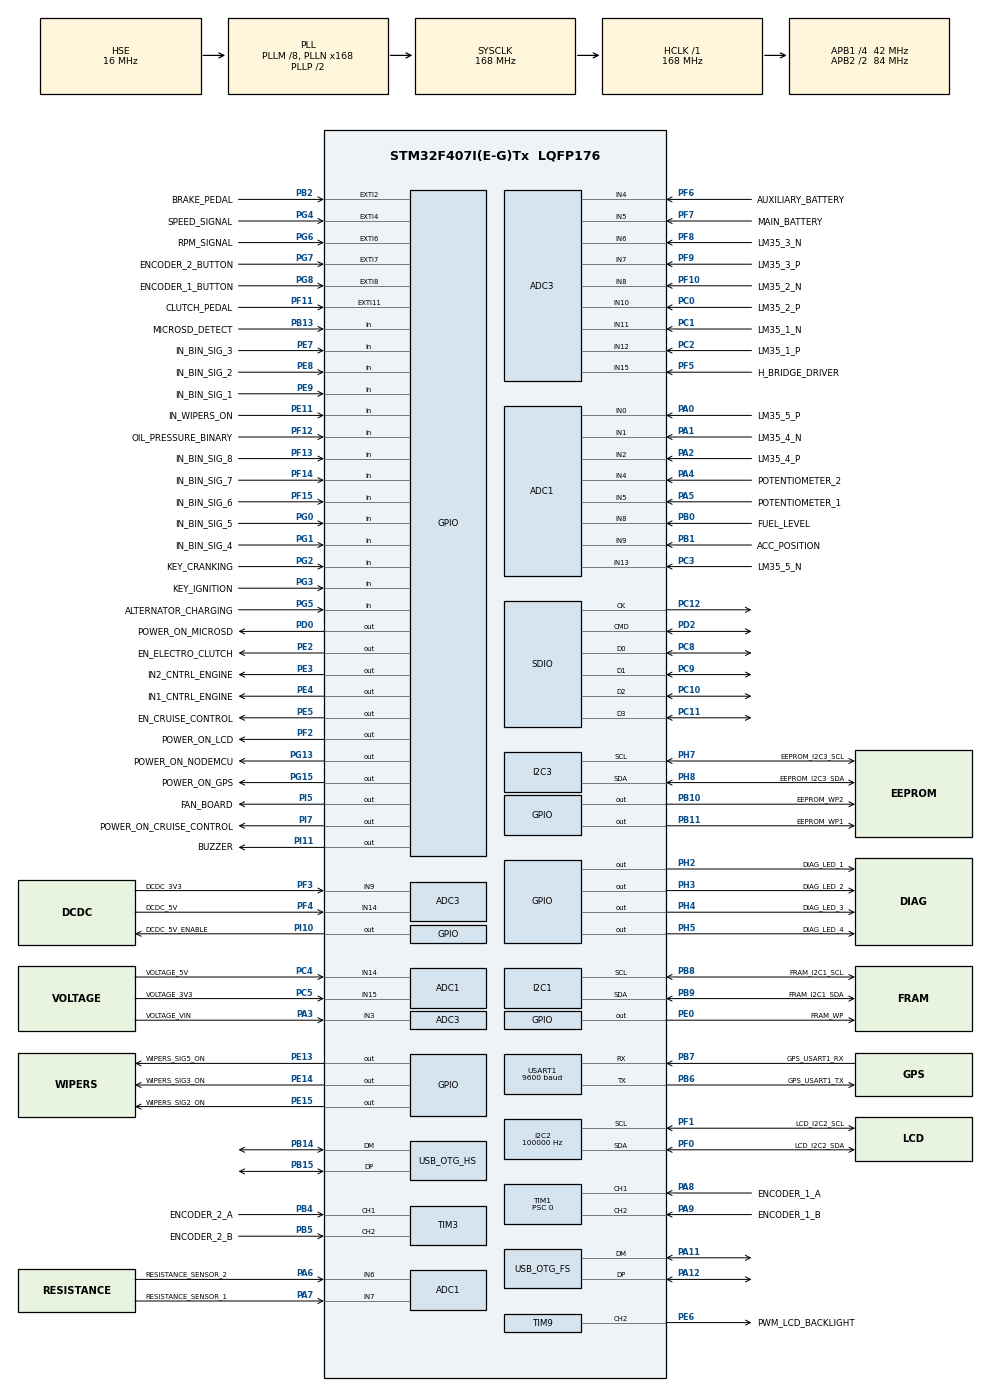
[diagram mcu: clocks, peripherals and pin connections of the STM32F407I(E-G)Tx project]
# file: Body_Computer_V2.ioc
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Dma.SDIO_RX.4.MemBurst=DMA_MBURST_INC4
FREERTOS.Queues01=Queue_EEPROM_read,5,EEPROM_data_struct,0,Dynamic,NULL,NULL;Queue_EEPROM_write,5,EEPROM_data_struct,0,Dynamic,NULL,NULL;Queue_error_snapshot_dump,5,Error_Code,0,Dynamic,NULL,NULL;Queue_diagnostic_snapshot_dump,5,Diagnostic_Snapshot_struct,0,Dynamic,NULL,NULL
PF4.Mode=IN14
FATFS._USE_LFN=3
NVIC.I2C1_EV_IRQn=true\:5\:0\:false\:false\:true\:true\:true\:true
FATFS0.BSP.api=Unknown
VP_ADC1_TempSens_Input.Mode=IN-TempSens
NVIC.TIM6_DAC_IRQn=true\:0\:0\:false\:false\:true\:false\:false\:true
PG8.Signal=GPXTI8
PG0.Signal=GPIO_Input
I2C2.NoStretchMode=I2C_NOSTRETCH_DISABLE
ADC1.SamplingTime-12\#ChannelRegularConversion=ADC_SAMPLETIME_480CYCLES
FREERTOS.configENABLE_FPU=1
PG15.GPIO_Label=POWER_ON_GPS
ADC1.Channel-5\#ChannelRegularConversion=ADC_CHANNEL_6
PF7.Signal=ADC3_IN5
ADC3.Rank-7\#ChannelRegularConversion=8
ADC1.Rank-11\#ChannelRegularConversion=12
RCC.APB2TimFreq_Value=168000000
PB6.Signal=USART1_TX
Dma.ADC1.0.Direction=DMA_PERIPH_TO_MEMORY
PD0.Signal=GPIO_Output
ADC3.ScanConvMode=ENABLE
Dma.ADC1.0.MemDataAlignment=DMA_MDATAALIGN_HALFWORD
FATFS0.BSP.ip=GPIO
NVIC.EXTI15_10_IRQn=true\:5\:0\:false\:false\:true\:true\:true\:true
Dma.I2C2_TX.2.Priority=DMA_PRIORITY_LOW
PB3.Mode=Trace_Asynchronous_SW
ADC1.ScanConvMode=ENABLE
PF1.GPIO_Label=LCD_I2C2_SCL
SH.ADCx_IN15.0=ADC1_IN15,IN15
PF12.GPIO_Label=OIL_PRESSURE_BINARY
I2C1.NoStretchMode=I2C_NOSTRETCH_ENABLE
PC4.GPIO_Label=VOLTAGE_5V
PE9.Signal=GPIO_Input
PB14.Mode=Device_Only_FS
ADC3.SamplingTime-5\#ChannelRegularConversion=ADC_SAMPLETIME_480CYCLES
PB1.GPIO_Label=ACC_POSITION
PE4.GPIO_Label=IN1_CNTRL_ENGINE
PG4.GPIO_Label=SPEED_SIGNAL
SH.ADCx_IN8.0=ADC1_IN8,IN8
PC9.Mode=SD_4_bits_Wide_bus
PA8.Signal=S_TIM1_CH1
VP_FREERTOS_VS_CMSIS_V1.Mode=CMSIS_V1
Dma.I2C2_RX.3.PeriphDataAlignment=DMA_PDATAALIGN_BYTE
Dma.SDIO_TX.5.PeriphDataAlignment=DMA_PDATAALIGN_WORD
TIM9.Prescaler=2
USB_DEVICE.USBD_SELF_POWERED-MSC_HS=0
Mcu.Package=LQFP176
PB9.Signal=I2C1_SDA
PB1.Signal=ADCx_IN9
NVIC.TimeBase=TIM6_DAC_IRQn
USB_DEVICE.VirtualMode-MSC_HS=Msc
ADC3.Rank-0\#ChannelRegularConversion=1
NVIC.TimeBaseIP=TIM6
PC11.Mode=SD_4_bits_Wide_bus
ADC3.DMAContinuousRequests=ENABLE
RCC.APB2CLKDivider=RCC_HCLK_DIV2
Dma.SDIO_RX.4.PeriphDataAlignment=DMA_PDATAALIGN_WORD
NVIC.EXTI2_IRQn=true\:5\:0\:false\:false\:true\:true\:true\:true
RCC.APB1TimFreq_Value=84000000
FREERTOS.configGENERATE_RUN_TIME_STATS=1
PF10.Mode=IN8
PH8.Mode=I2C
PA4.GPIO_Label=POTENTIOMETER_2
ADC1.EOCSelection=ADC_EOC_SEQ_CONV
Dma.ADC3.1.Priority=DMA_PRIORITY_LOW
ADC1.Rank-4\#ChannelRegularConversion=5
TIM9.Channel-PWM\ Generation2\ CH2=TIM_CHANNEL_2
FATFS0.BSP.STBoard=false
FREERTOS.Tasks01=My_StartUp_Task,2,128,StartStartUpTask,Default,NULL,Dynamic,NULL,NULL;My_CruiseCntrl,1,256,StartCruiseCntrlTask,As external,NULL,Dynamic,NULL,NULL;My_500ms_Task,0,128,Start500msTask,As external,NULL,Dynamic,NULL,NULL;My_LCD_Task,0,512,StartLCDTask,As external,NULL,Dynamic,NULL,NULL;My_GPS_Task,0,448,StartGPSTask,As external,NULL,Dynamic,NULL,NULL;My_EEPROM_Task,1,128,StartEEPROMTask,As external,NULL,Dynamic,NULL,NULL;My_DumpToEEPROM,-1,128,StartDumpToEEPROMTask,As external,NULL,Dynamic,NULL,NULL;My_DumpToSDCard,-1,1536,StartDumpToSDCardTask,As external,NULL,Dynamic,NULL,NULL;My_Measure_Task,0,384,StartMeasureTask,As external,NULL,Dynamic,NULL,NULL;My_50ms_Task,0,128,Start50msTask,As external,NULL,Dynamic,NULL,NULL;My_DiagCheck_Ta,1,256,StartDiagCheckTask,As external,NULL,Dynamic,NULL,NULL;My_AlarmControl,0,256,StartAlarmControlTask,As external,NULL,Dynamic,NULL,NULL
SH.ADCx_IN6.0=ADC1_IN6,IN6
PG5.Signal=GPIO_Input
ADC3.Rank-6\#ChannelRegularConversion=7
FATFS0.BSP.mode=Input
FREERTOS.INCLUDE_vTaskDelayUntil=1
PC2.Signal=ADCx_IN12
Dma.SDIO_TX.5.Direction=DMA_MEMORY_TO_PERIPH
USB_OTG_HS.VirtualMode-Device_Only_FS=Device_Only_FS
PF8.GPIO_Label=LM35_3_N
PG8.GPIO_PuPd=GPIO_NOPULL
TIM9.Pulse-PWM\ Generation2\ CH2=1
PB8.GPIO_Label=FRAM_I2C1_SCL
PA8.GPIO_Label=ENCODER_1_A
TIM3.IC2Filter=15
ADC3.SamplingTime-6\#ChannelRegularConversion=ADC_SAMPLETIME_480CYCLES
PE8.GPIO_Label=IN_BIN_SIG_2
Dma.ADC1.0.Priority=DMA_PRIORITY_LOW
SDIO.ClockDiv=3
NVIC.DMA2_Stream6_IRQn=true\:5\:0\:false\:false\:true\:true\:false\:true
PB14.Signal=USB_OTG_HS_DM
PA5.Signal=ADCx_IN5
TIM3.IC1Filter=15
PC12.Mode=SD_4_bits_Wide_bus
ADC1.Rank-12\#ChannelRegularConversion=13
PI7.Signal=GPIO_Output
PE14.Signal=GPIO_Output
ADC3.Channel-5\#ChannelRegularConversion=ADC_CHANNEL_4
PB4.GPIO_Label=ENCODER_2_A
PG7.GPIO_Label=ENCODER_2_BUTTON
PF4.GPIO_Label=DCDC_5V
PA1.GPIO_Label=LM35_4_N
SH.ADCx_IN4.0=ADC1_IN4,IN4
FREERTOS.configUSE_MUTEXES=0
PF13.Signal=GPIO_Input
ADC1.Rank-9\#ChannelRegularConversion=10
FREERTOS.INCLUDE_uxTaskGetStackHighWaterMark2=1
PC8.Mode=SD_4_bits_Wide_bus
ADC3.Rank-1\#ChannelRegularConversion=2
Dma.SDIO_RX.4.PeriphInc=DMA_PINC_DISABLE
ADC1.master=1
PA5.GPIO_Label=POTENTIOMETER_1
Dma.SDIO_RX.4.FIFOThreshold=DMA_FIFO_THRESHOLD_FULL
PE5.GPIO_Label=EN_CRUISE_CONTROL
ProjectManager.HeapSize=0x2000
ADC3.EOCSelection=ADC_EOC_SEQ_CONV
NVIC.PriorityGroup=NVIC_PRIORITYGROUP_4
PF0.GPIO_Label=LCD_I2C2_SDA
PI11.GPIO_Label=BUZZER
PE3.Signal=GPIO_Output
PF4.Signal=ADC3_IN14
ADC1.SamplingTime-9\#ChannelRegularConversion=ADC_SAMPLETIME_480CYCLES
PD2.Signal=SDIO_CMD
ADC1.Rank-5\#ChannelRegularConversion=6
FATFS0.BSP.name=Detect_SDIO
Mcu.Family=STM32F4
Dma.SDIO_TX.5.MemInc=DMA_MINC_ENABLE
NVIC.OTG_HS_IRQn=true\:5\:0\:false\:false\:true\:true\:false\:true
USB_DEVICE.CLASS_NAME_FS=DFU
ADC1.ContinuousConvMode=ENABLE
ADC3.Channel-3\#ChannelRegularConversion=ADC_CHANNEL_15
PG2.Signal=GPIO_Input
ADC3.Channel-11\#ChannelRegularConversion=ADC_CHANNEL_7
PE11.GPIO_Label=IN_WIPERS_ON
USART1.BaudRate=9600
PD0.GPIO_Label=POWER_ON_MICROSD
TIM1.EncoderMode=TIM_ENCODERMODE_TI12
PA11.Mode=Device_Only
PB13.GPIO_Label=MICROSD_DETECT
PG5.GPIO_Label=ALTERNATOR_CHARGING
PB15.Signal=USB_OTG_HS_DP
VP_USB_DEVICE_VS_USB_DEVICE_DFU_FS.Mode=DFU_FS
ADC3.Channel-0\#ChannelRegularConversion=ADC_CHANNEL_3
PG15.Signal=GPIO_Output
ADC3.Rank-2\#ChannelRegularConversion=3
Dma.SDIO_TX.5.FIFOThreshold=DMA_FIFO_THRESHOLD_FULL
ADC3.Channel-6\#ChannelRegularConversion=ADC_CHANNEL_11
Dma.ADC3.1.PeriphDataAlignment=DMA_PDATAALIGN_HALFWORD
TIM1.Prescaler=0
PE11.GPIO_PuPd=GPIO_PULLDOWN
ADC1.Channel-3\#ChannelRegularConversion=ADC_CHANNEL_4
SH.ADCx_IN3.0=ADC3_IN3,IN3
Dma.SDIO_RX.4.FIFOMode=DMA_FIFOMODE_ENABLE
PG5.GPIO_PuPd=GPIO_PULLDOWN
TIM7.Period=4199
Dma.SDIO_RX.4.MemDataAlignment=DMA_MDATAALIGN_WORD
ADC1.Channel-0\#ChannelRegularConversion=ADC_CHANNEL_14
RCC.HSE_VALUE=16000000
FREERTOS.configUSE_TIMERS=1
PE13.GPIO_PuPd=GPIO_PULLDOWN
FREERTOS.configENABLE_BACKWARD_COMPATIBILITY=0
PF9.Mode=IN7
Dma.I2C2_TX.2.MemInc=DMA_MINC_ENABLE
PA14.Mode=Trace_Asynchronous_SW
PH7.GPIO_Label=EEPROM_I2C3_SCL
PF11.Signal=GPXTI11
PG6.GPIO_ModeDefaultEXTI=GPIO_MODE_IT_RISING
PB7.Signal=USART1_RX
Dma.SDIO_RX.4.Mode=DMA_PFCTRL
SH.S_TIM3_CH1.0=TIM3_CH1,Encoder_Interface
NVIC.DMA1_Stream7_IRQn=true\:5\:0\:false\:false\:true\:true\:false\:true
PH1-OSC_OUT.Mode=HSE-External-Oscillator
PB7.GPIO_Label=GPS_USART1_RX
PA6.Signal=ADCx_IN6
NVIC.OTG_FS_IRQn=true\:5\:0\:false\:false\:true\:true\:false\:true
IWDG.Reload=600
USB_DEVICE.CLASS_NAME_HS=MSC
PF8.Signal=ADC3_IN6
PG0.GPIO_Label=IN_BIN_SIG_5
Dma.SDIO_RX.4.Direction=DMA_PERIPH_TO_MEMORY
PG4.GPIO_ModeDefaultEXTI=GPIO_MODE_IT_RISING_FALLING
SH.ADCx_IN1.0=ADC1_IN1,IN1
PB5.GPIO_Label=ENCODER_2_B
Dma.Request2=I2C2_TX
Dma.Request1=ADC3
Dma.Request4=SDIO_RX
Dma.Request3=I2C2_RX
Dma.SDIO_RX.4.Priority=DMA_PRIORITY_LOW
Dma.Request5=SDIO_TX
PC5.Signal=ADCx_IN15
PE7.Signal=GPIO_Input
ADC1.Rank-6\#ChannelRegularConversion=7
Dma.Request0=ADC1
PF3.GPIO_Label=DCDC_3V3
ADC1.SamplingTime-8\#ChannelRegularConversion=ADC_SAMPLETIME_480CYCLES
PE2.GPIO_Label=EN_ELECTRO_CLUTCH
PB4.Signal=S_TIM3_CH1
PG2.GPIO_Label=KEY_CRANKING
PA3.Signal=ADCx_IN3
Dma.SDIO_TX.5.Mode=DMA_PFCTRL
ADC3.SamplingTime-3\#ChannelRegularConversion=ADC_SAMPLETIME_480CYCLES
SH.ADCx_IN13.0=ADC1_IN13,IN13
PG7.Signal=GPXTI7
ADC1.Rank-10\#ChannelRegularConversion=11
ADC1.Rank-8\#ChannelRegularConversion=9
PC11.Signal=SDIO_D3
PC8.Signal=SDIO_D0
PC10.Mode=SD_4_bits_Wide_bus
Dma.I2C2_TX.2.Mode=DMA_NORMAL
Dma.I2C2_RX.3.PeriphInc=DMA_PINC_DISABLE
PE14.GPIO_Label=WIPERS_SIG3_ON
ADC3.SamplingTime-10\#ChannelRegularConversion=ADC_SAMPLETIME_480CYCLES
PF5.Mode=IN15
NVIC.SDIO_IRQn=true\:5\:0\:false\:false\:true\:true\:true\:true
Dma.SDIO_RX.4.Instance=DMA2_Stream3
FATFS0.BSP.instance=PB13
PG8.GPIO_Label=ENCODER_1_BUTTON
PA13.Signal=SYS_JTMS-SWDIO
Dma.ADC1.0.PeriphDataAlignment=DMA_PDATAALIGN_HALFWORD
ADC3.SamplingTime-0\#ChannelRegularConversion=ADC_SAMPLETIME_480CYCLES
SH.S_TIM1_CH1.0=TIM1_CH1,Encoder_Interface
PF6.Signal=ADC3_IN4
FREERTOS.configRECORD_STACK_HIGH_ADDRESS=1
PB10.GPIO_Label=EEPROM_WP2
FREERTOS.configUSE_TRACE_FACILITY=1
PH8.Signal=I2C3_SDA
PB9.Mode=I2C
PF9.GPIO_Label=LM35_3_P
PA1.Signal=ADCx_IN1
PD2.Mode=SD_4_bits_Wide_bus
board=custom
Dma.I2C2_TX.2.PeriphInc=DMA_PINC_DISABLE
RCC.VCOOutputFreq_Value=336000000
PH4.GPIO_Label=DIAG_LED_3
PB15.Mode=Device_Only_FS
ADC1.Channel-12\#ChannelRegularConversion=ADC_CHANNEL_TEMPSENSOR
SH.ADCx_IN11.0=ADC3_IN11,IN11
PC1.GPIO_Label=LM35_1_N
PF15.GPIO_Label=IN_BIN_SIG_6
Dma.ADC3.1.MemInc=DMA_MINC_ENABLE
ADC3.SamplingTime-8\#ChannelRegularConversion=ADC_SAMPLETIME_480CYCLES
PE14.GPIO_PuPd=GPIO_PULLDOWN
PF1.Signal=I2C2_SCL
ADC1.NbrOfConversion=13
Dma.ADC3.1.Mode=DMA_CIRCULAR
PE0.Signal=GPIO_Output
PE7.GPIO_Label=IN_BIN_SIG_3
FATFS._MAX_SS=512
RCC.48MHZClocksFreq_Value=48000000
RCC.SYSCLKFreq_VALUE=168000000
ADC1.SamplingTime-3\#ChannelRegularConversion=ADC_SAMPLETIME_480CYCLES
ADC1.Rank-3\#ChannelRegularConversion=4
NVIC.EXTI9_5_IRQn=true\:5\:0\:false\:false\:true\:true\:true\:true
Dma.ADC1.0.MemInc=DMA_MINC_ENABLE
Dma.SDIO_TX.5.FIFOMode=DMA_FIFOMODE_ENABLE
PB2.GPIO_Label=BRAKE_PEDAL
PG4.GPIO_PuPd=GPIO_PULLDOWN
NVIC.I2C2_EV_IRQn=true\:5\:0\:false\:false\:true\:true\:true\:true
RCC.HSI_VALUE=16000000
RCC.PLLQ=7
PH3.Signal=GPIO_Output
RCC.PLLM=8
RCC.PLLN=168
ADC3.Rank-11\#ChannelRegularConversion=12
PE5.GPIO_Speed=GPIO_SPEED_FREQ_HIGH
ADC3.NbrOfConversionFlag=1
Dma.SDIO_RX.4.PeriphBurst=DMA_PBURST_INC4
Dma.SDIO_TX.5.Instance=DMA2_Stream6
PA3.GPIO_Label=VOLTAGE_VIN
PH0-OSC_IN.Signal=RCC_OSC_IN
VP_SYS_VS_tim6.Mode=TIM6
VP_FATFS_VS_SDIO.Mode=SDIO
PG4.Signal=GPXTI4
ADC1.SamplingTime-6\#ChannelRegularConversion=ADC_SAMPLETIME_480CYCLES
NVIC.DMA1_Stream2_IRQn=true\:5\:0\:false\:false\:true\:true\:false\:true
PC12.Signal=SDIO_CK
PG6.GPIO_Label=RPM_SIGNAL
PA6.GPIO_Label=RESISTANCE_SENSOR_2
PB6.GPIO_Label=GPS_USART1_TX
PB13.Signal=GPIO_Input
PG13.Signal=GPIO_Output
PE6.GPIO_Label=PWM_LCD_BACKLIGHT
PF6.GPIO_Label=AUXILIARY_BATTERY 
ADC1.Channel-8\#ChannelRegularConversion=ADC_CHANNEL_1
RCC.SYSCLKSource=RCC_SYSCLKSOURCE_PLLCLK
ADC3.Channel-8\#ChannelRegularConversion=ADC_CHANNEL_8
PH5.Signal=GPIO_Output
ADC1.Channel-2\#ChannelRegularConversion=ADC_CHANNEL_5
PB6.Mode=Asynchronous
PC3.Signal=ADCx_IN13
PE5.Signal=GPIO_Output
Dma.I2C2_TX.2.Direction=DMA_MEMORY_TO_PERIPH
PF10.GPIO_Label=LM35_2_N
PB2.Signal=GPXTI2
FATFS0.BSP.i2caddr=0
ADC3.SamplingTime-2\#ChannelRegularConversion=ADC_SAMPLETIME_480CYCLES
PG6.GPIO_PuPd=GPIO_PULLDOWN
Dma.I2C2_RX.3.Priority=DMA_PRIORITY_LOW
Dma.ADC1.0.PeriphInc=DMA_PINC_DISABLE
ADC3.ContinuousConvMode=ENABLE
PE2.Signal=GPIO_Output
PF8.Mode=IN6
ADC3.SamplingTime-9\#ChannelRegularConversion=ADC_SAMPLETIME_480CYCLES
PF3.Signal=ADC3_IN9
ADC3.Channel-2\#ChannelRegularConversion=ADC_CHANNEL_14
ADC3.Rank-4\#ChannelRegularConversion=5
ADC1.SamplingTime-0\#ChannelRegularConversion=ADC_SAMPLETIME_480CYCLES
SH.ADCx_IN14.0=ADC1_IN14,IN14
Dma.I2C2_TX.2.FIFOMode=DMA_FIFOMODE_DISABLE
FATFS0.BSP.solution=PB13
SH.ADCx_IN9.0=ADC1_IN9,IN9
PH2.Signal=GPIO_Output
Dma.SDIO_TX.5.PeriphInc=DMA_PINC_DISABLE
Dma.I2C2_RX.3.MemInc=DMA_MINC_ENABLE
PF14.Signal=GPIO_Input
Dma.ADC1.0.FIFOMode=DMA_FIFOMODE_DISABLE
Dma.I2C2_TX.2.Instance=DMA1_Stream7
PI11.Signal=GPIO_Output
NVIC.USART1_IRQn=true\:5\:0\:false\:false\:true\:true\:true\:true
TIM9.Period=9999
PI10.GPIO_Label=DCDC_5V_ENABLE
ADC1.Channel-10\#ChannelRegularConversion=ADC_CHANNEL_13
FREERTOS.configTIMER_QUEUE_LENGTH=50
NVIC.EXTI4_IRQn=true\:5\:0\:false\:false\:true\:true\:true\:true
Dma.I2C2_TX.2.MemDataAlignment=DMA_MDATAALIGN_BYTE
Dma.SDIO_TX.5.MemDataAlignment=DMA_MDATAALIGN_WORD
Dma.ADC1.0.Instance=DMA2_Stream0
ADC1.Rank-0\#ChannelRegularConversion=1
ADC3.Rank-10\#ChannelRegularConversion=11
PA9.GPIO_Label=ENCODER_1_B
FREERTOS.configCHECK_FOR_STACK_OVERFLOW=1
PB11.GPIO_Label=EEPROM_WP1
PF14.GPIO_Label=IN_BIN_SIG_7
NVIC.DMA2_Stream1_IRQn=true\:5\:0\:false\:false\:true\:true\:false\:true
PC0.Signal=ADCx_IN10
RCC.APB1CLKDivider=RCC_HCLK_DIV4
PF13.GPIO_Label=IN_BIN_SIG_8
PG13.GPIO_Label=POWER_ON_NODEMCU
VP_USB_DEVICE_VS_USB_DEVICE_MSC_HS.Mode=MSC_HS
PA0-WKUP.GPIO_Label=LM35_5_P
PA0-WKUP.Signal=ADCx_IN0
ADC1.Channel-7\#ChannelRegularConversion=ADC_CHANNEL_9
PF1.Mode=I2C
SH.S_TIM9_CH2.0=TIM9_CH2,PWM Generation2 CH2
SH.ADCx_IN7.0=ADC1_IN7,IN7
PA9.Signal=S_TIM1_CH2
ADC3.NbrOfConversion=12
Dma.ADC3.1.FIFOMode=DMA_FIFOMODE_DISABLE
PE9.GPIO_Label=IN_BIN_SIG_1
Dma.SDIO_TX.5.Priority=DMA_PRIORITY_LOW
Dma.ADC3.1.Instance=DMA2_Stream1
PB10.Signal=GPIO_Output
ADC3.Rank-9\#ChannelRegularConversion=10
FATFS.BSP.number=1
PE15.Signal=GPIO_Output
PE8.Signal=GPIO_Input
Dma.ADC3.1.MemDataAlignment=DMA_MDATAALIGN_HALFWORD
TIM1.IC2Filter=15
Dma.ADC3.1.PeriphInc=DMA_PINC_DISABLE
ADC1.SamplingTime-10\#ChannelRegularConversion=ADC_SAMPLETIME_480CYCLES
ADC1.DMAContinuousRequests=ENABLE
ADC3.Rank-5\#ChannelRegularConversion=6
PA13.Mode=Trace_Asynchronous_SW
ADC3.Channel-1\#ChannelRegularConversion=ADC_CHANNEL_9
PA4.Signal=ADCx_IN4
ADC1.SamplingTime-1\#ChannelRegularConversion=ADC_SAMPLETIME_480CYCLES
PB5.Signal=S_TIM3_CH2
PE13.GPIO_Label=WIPERS_SIG5_ON
TIM1.IC1Filter=15
USART1.VirtualMode=VM_ASYNC
ADC1.Rank-1\#ChannelRegularConversion=2
PA11.Signal=USB_OTG_FS_DM
Dma.SDIO_TX.5.MemBurst=DMA_MBURST_INC4
ADC1.SamplingTime-5\#ChannelRegularConversion=ADC_SAMPLETIME_480CYCLES
PF6.Mode=IN4
PF9.Signal=ADC3_IN7
FREERTOS.Timers01=My_Timer_ENC_Menu_Button,ENC_Menu_Button_LongPress_Callback,osTimerOnce,Default,NULL,Dynamic,NULL;My_Timer_ENC_Cruise_Button,ENC_Cruise_Button_LongPress_Callback,osTimerOnce,Default,NULL,Dynamic,NULL;My_Timer_carWaterTempValueCheck,Timer_carWaterTempValueCheck,osTimerOnce,As external,NULL,Dynamic,NULL;My_Timer_carOilTempValueCheck,Timer_carOilTempValueCheck,osTimerOnce,As external,NULL,Dynamic,NULL;My_Timer_carOilAnalogPressureValueCheck,Timer_carOilAnalogPressureValueCheck,osTimerOnce,As external,NULL,Dynamic,NULL;My_Timer_carMainBattVoltageValueCheck,Timer_carMainBattVoltageValueCheck,osTimerOnce,As external,NULL,Dynamic,NULL;My_Timer_carFuelLevelValueCheck,Timer_carFuelLevelValueCheck,osTimerOnce,As external,NULL,Dynamic,NULL;My_Timer_board3V3VoltageValueCheck,Timer_board3V3VoltageValueCheck,osTimerOnce,As external,NULL,Dynamic,NULL;My_Timer_board5VVoltageValueCheck,Timer_board5VVoltageValueCheck,osTimerOnce,As external,NULL,Dynamic,NULL;My_Timer_boardVinVoltageValueCheck,Timer_boardVinVoltageValueCheck,osTimerOnce,As external,NULL,Dynamic,NULL;My_Timer_board3V3TempValueCheck,Timer_board3V3TempValueCheck,osTimerOnce,As external,NULL,Dynamic,NULL;My_Timer_board5VTempValueCheck,Timer_board5VTempValueCheck,osTimerOnce,As external,NULL,Dynamic,NULL;My_Timer_boardHBridgeTempValueCheck,Timer_boardHBridgeTempValueCheck,osTimerOnce,As external,NULL,Dynamic,NULL;My_Timer_carOilBinaryPressureValueCheck,Timer_carOilBinaryPressureValueCheck,osTimerOnce,As external,NULL,Dynamic,NULL;My_Timer_Buzzer,Timer_Buzzer,osTimerOnce,As external,NULL,Dynamic,NULL;My_Timer_carAuxBattVoltageValueCheck,Timer_carAuxBattVoltageValueCheck,osTimerOnce,As external,NULL,Dynamic,NULL;My_Timer_LCD_Backlight,Timer_LCD_Backlight,osTimerOnce,As external,NULL,Dynamic,NULL;My_Timer_WIPERS,Timer_WIPERS,osTimerOnce,As external,NULL,Dynamic,NULL
SH.ADCx_IN5.0=ADC1_IN5,IN5
PB8.Mode=I2C
PF12.GPIO_PuPd=GPIO_PULLDOWN
PC3.GPIO_Label=LM35_5_N
PG3.GPIO_Label=KEY_IGNITION
PB0.Signal=ADCx_IN8
PC1.Signal=ADCx_IN11
PH2.GPIO_Label=DIAG_LED_1
RCC.CortexFreq_Value=168000000
PG6.Signal=GPXTI6
ADC3.SamplingTime-7\#ChannelRegularConversion=ADC_SAMPLETIME_480CYCLES
SH.ADCx_IN2.0=ADC1_IN2,IN2
PC10.Signal=SDIO_D2
VP_IWDG_VS_IWDG.Mode=IWDG_Activate
ADC3.SamplingTime-11\#ChannelRegularConversion=ADC_SAMPLETIME_480CYCLES
TIM3.EncoderMode=TIM_ENCODERMODE_TI12
PC0.GPIO_Label=LM35_2_P
PB0.GPIO_Label=FUEL_LEVEL
PH5.GPIO_Label=DIAG_LED_4
PI5.GPIO_Label=FAN_BOARD
PB11.Signal=GPIO_Output
FATFS._NORTC_YEAR=2000
ProjectManager.StackSize=0x4000
VP_TIM7_VS_ClockSourceINT.Mode=Enable_Timer
ADC3.SamplingTime-4\#ChannelRegularConversion=ADC_SAMPLETIME_480CYCLES
PB2.GPIO_ModeDefaultEXTI=GPIO_MODE_IT_RISING
PA12.Signal=USB_OTG_FS_DP
PE5.GPIO_PuPd=GPIO_PULLDOWN
FREERTOS.configUSE_STATS_FORMATTING_FUNCTIONS=1
RCC.HCLKFreq_Value=168000000
PF11.GPIO_Label=CLUTCH_PEDAL
PF2.GPIO_PuPd=GPIO_PULLDOWN
PF12.Signal=GPIO_Input
FREERTOS.configUSE_MALLOC_FAILED_HOOK=1
NVIC.DMA2_Stream0_IRQn=true\:5\:0\:false\:false\:true\:true\:false\:true
PF11.GPIO_ModeDefaultEXTI=GPIO_MODE_IT_RISING
RCC.AHBFreq_Value=168000000
PH0-OSC_IN.Mode=HSE-External-Oscillator
ADC3.SamplingTime-1\#ChannelRegularConversion=ADC_SAMPLETIME_480CYCLES
USB_DEVICE.USBD_DFU_MAX_ITF_NUM-DFU_FS=1
PG7.GPIO_ModeDefaultEXTI=GPIO_MODE_IT_RISING_FALLING
ADC1.SamplingTime-4\#ChannelRegularConversion=ADC_SAMPLETIME_480CYCLES
NVIC.I2C3_EV_IRQn=true\:5\:0\:false\:false\:true\:true\:true\:true
ADC1.Channel-6\#ChannelRegularConversion=ADC_CHANNEL_8
ADC1.Rank-2\#ChannelRegularConversion=3
ADC3.Channel-9\#ChannelRegularConversion=ADC_CHANNEL_10
PE13.Signal=GPIO_Output
PF7.GPIO_Label=MAIN_BATTERY
ADC3.Rank-8\#ChannelRegularConversion=9
PI5.Signal=GPIO_Output
SH.ADCx_IN0.0=ADC1_IN0,IN0
PE4.Signal=GPIO_Output
FREERTOS.configTOTAL_HEAP_SIZE=32768
PH7.Mode=I2C
ADC1.SamplingTime-11\#ChannelRegularConversion=ADC_SAMPLETIME_480CYCLES
Dma.ADC3.1.Direction=DMA_PERIPH_TO_MEMORY
Dma.I2C2_RX.3.Direction=DMA_PERIPH_TO_MEMORY
PA2.GPIO_Label=LM35_4_P
ADC1.Channel-11\#ChannelRegularConversion=ADC_CHANNEL_0
PF5.GPIO_Label=H_BRIDGE_DRIVER
USB_OTG_FS.VirtualMode=Device_Only
PE0.GPIO_Label=FRAM_WP
ADC3.ClockPrescaler=ADC_CLOCK_SYNC_PCLK_DIV4
PH3.GPIO_Label=DIAG_LED_2
PF5.Signal=ADC3_IN15
USB_DEVICE.VirtualModeHS=Msc_HS
PH7.Signal=I2C3_SCL
Dma.I2C2_RX.3.Mode=DMA_NORMAL
PF0.Signal=I2C2_SDA
USB_DEVICE.USBD_MAX_NUM_CONFIGURATION-MSC_HS=1
USB_OTG_HS.dma_enable-Device_Only_FS=DISABLE
PC2.GPIO_Label=LM35_1_P
NVIC.TIM7_IRQn=true\:5\:0\:false\:false\:true\:true\:true\:true
ADC3.Channel-7\#ChannelRegularConversion=ADC_CHANNEL_12
I2C3.I2C_Mode=I2C_Standard
PF3.Mode=IN9
PB9.GPIO_Label=FRAM_I2C1_SDA
ADC1.Channel-4\#ChannelRegularConversion=ADC_CHANNEL_7
Dma.I2C2_RX.3.Instance=DMA1_Stream2
USB_DEVICE.VirtualModeFS=Dfu_FS
PG3.Signal=GPIO_Input
PG1.Signal=GPIO_Input
PC4.Signal=ADCx_IN14
PI10.Signal=GPIO_Output
ADC3.Rank-3\#ChannelRegularConversion=4
ADC1.SamplingTime-2\#ChannelRegularConversion=ADC_SAMPLETIME_480CYCLES
FREERTOS.INCLUDE_uxTaskGetStackHighWaterMark=1
Dma.I2C2_RX.3.MemDataAlignment=DMA_MDATAALIGN_BYTE
Dma.SDIO_RX.4.MemInc=DMA_MINC_ENABLE
PF7.Mode=IN5
PH8.GPIO_Label=EEPROM_I2C3_SDA
SH.ADCx_IN12.0=ADC3_IN12,IN12
PE15.GPIO_Label=WIPERS_SIG2_ON
PH4.Signal=GPIO_Output
Dma.I2C2_TX.2.PeriphDataAlignment=DMA_PDATAALIGN_BYTE
ProjectManager.TargetToolchain=STM32CubeIDE
ADC3.Channel-4\#ChannelRegularConversion=ADC_CHANNEL_5
FREERTOS.configTIMER_TASK_STACK_DEPTH=512
Dma.ADC1.0.Mode=DMA_CIRCULAR
ADC1.Channel-1\#ChannelRegularConversion=ADC_CHANNEL_15
PF2.Signal=GPIO_Output
Dma.I2C2_RX.3.FIFOMode=DMA_FIFOMODE_DISABLE
NVIC.DMA2_Stream3_IRQn=true\:5\:0\:false\:false\:true\:true\:false\:true
PE11.Signal=GPIO_Input
RCC.LSE_VALUE=32768
SH.S_TIM3_CH2.0=TIM3_CH2,Encoder_Interface
PG1.GPIO_Label=IN_BIN_SIG_4
FATFS._FS_NORTC=1
FATFS.USE_DMA_CODE_SD=1
RCC.APB2Freq_Value=84000000
USB_DEVICE.VirtualMode-DFU_FS=Dfu
SH.S_TIM1_CH2.0=TIM1_CH2,Encoder_Interface
PF10.Signal=ADC3_IN8
I2C2.ClockSpeed=100000
PH1-OSC_OUT.Signal=RCC_OSC_OUT
PI7.GPIO_Label=POWER_ON_CRUISE_CONTROL
PF15.Signal=GPIO_Input
PG8.GPIO_ModeDefaultEXTI=GPIO_MODE_IT_RISING_FALLING
PE6.Signal=S_TIM9_CH2
Mcu.Name=STM32F407I(E-G)Tx
TIM9.ClockDivision=TIM_CLOCKDIVISION_DIV1
PA2.Signal=ADCx_IN2
ADC1.Channel-9\#ChannelRegularConversion=ADC_CHANNEL_2
PB3.Signal=SYS_JTDO-SWO
PA7.GPIO_Label=RESISTANCE_SENSOR_1
PA12.Mode=Device_Only
Dma.SDIO_TX.5.PeriphBurst=DMA_PBURST_INC4
PC5.GPIO_Label=VOLTAGE_3V3
PB7.Mode=Asynchronous
PA14.Signal=SYS_JTCK-SWCLK
SH.ADCx_IN10.0=ADC3_IN10,IN10
PF0.Mode=I2C
ADC3.Channel-10\#ChannelRegularConversion=ADC_CHANNEL_6
ADC1.Rank-7\#ChannelRegularConversion=8
ADC1.NbrOfConversionFlag=1
IWDG.Prescaler=IWDG_PRESCALER_32
PB8.Signal=I2C1_SCL
PE3.GPIO_Label=IN2_CNTRL_ENGINE
PC9.Signal=SDIO_D1
ADC1.SamplingTime-7\#ChannelRegularConversion=ADC_SAMPLETIME_480CYCLES
RCC.APB1Freq_Value=42000000
ADC1.ClockPrescaler=ADC_CLOCK_SYNC_PCLK_DIV4
PA7.Signal=ADCx_IN7
PF2.GPIO_Label=POWER_ON_LCD

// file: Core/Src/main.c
/* USER CODE BEGIN Header */
/**
  ******************************************************************************
  * @file           : main.c
  * @brief          : Main program body
  ******************************************************************************
  * @attention
  *
  * <h2><center>&copy; Copyright (c) 2021 STMicroelectronics.
  * All rights reserved.</center></h2>
  *
  * This software component is licensed by ST under BSD 3-Clause license,
  * the "License"; You may not use this file except in compliance with the
  * License. You may obtain a copy of the License at:
  *                        opensource.org/licenses/BSD-3-Clause
  *
  ******************************************************************************
  */
/* USER CODE END Header */
#include "main.h"
#include "cmsis_os.h"
#include "adc.h"
#include "dma.h"
#include "fatfs.h"
#include "i2c.h"
#include "iwdg.h"
#include "sdio.h"
#include "tim.h"
#include "usart.h"
#include "usb_device.h"
#include "gpio.h"

/* USER CODE BEGIN Includes */

#include "../GPS/GPS_Parsing.h"
#include "Init_Functions.h"

/* USER CODE END Includes */

/* USER CODE BEGIN PV */

extern volatile ENCButton_struct ENC_button_menu;
extern volatile ENCButton_struct ENC_button_cruise;
extern volatile uint16_t ADC1Measures[NO_OF_ADC1_MEASURES];
extern volatile uint16_t ADC3Measures[NO_OF_ADC3_MEASURES];
extern GPS_data_struct GPS;
extern uint64_t Tim7_Counter_100us;
extern osTimerId My_Timer_ENC_Menu_ButtonHandle;
extern osTimerId My_Timer_ENC_Cruise_ButtonHandle;

extern volatile uint32_t RPM_counter;
extern volatile uint32_t SPEED_counter;

extern volatile CruiseControlParameters_struct cruiseControlParam;

extern boolean backlightOnRequest;

/* USER CODE END PV */

void SystemClock_Config(void);
void MX_FREERTOS_Init(void);
/* USER CODE BEGIN PFP */

void HAL_UART_RxCpltCallback(UART_HandleTypeDef *huart);
void HAL_GPIO_EXTI_Callback(uint16_t GPIO_Pin);

extern void Complete_Shutdown(void);

/* USER CODE END PFP */

int main(void)
{
  /* USER CODE BEGIN 1 */
	Error_Code error = NO_ERROR;
  /* USER CODE END 1 */

  /* MCU Configuration--------------------------------------------------------*/

  /* Reset of all peripherals, Initializes the Flash interface and the Systick. */
  HAL_Init();

  /* Configure the system clock */
  SystemClock_Config();

  /* Initialize all configured peripherals */
  MX_GPIO_Init();
  MX_DMA_Init();
  MX_ADC1_Init();
  MX_ADC3_Init();
  MX_I2C2_Init();
  MX_SDIO_SD_Init();
  MX_I2C3_Init();
  MX_USART1_UART_Init();
  MX_I2C1_Init();
  MX_FATFS_Init();
  MX_TIM1_Init();
  MX_TIM7_Init();
  MX_TIM3_Init();
  MX_TIM9_Init();
  MX_IWDG_Init();
  /* USER CODE BEGIN 2 */

	error = (Error_Code)HAL_TIM_Encoder_Start(&htim1, TIM_CHANNEL_ALL);
	if (NO_ERROR != error)
	{
		error = TIM__ENCODER_START_FAIL;
		my_error_handler(error);
	}

	error = (Error_Code)HAL_TIM_Encoder_Start(&htim3, TIM_CHANNEL_ALL);
	if (NO_ERROR != error)
	{
		error = TIM__ENCODER_START_FAIL;
		my_error_handler(error);
	}

	/* There is no Calibration services in STM32F407IGTx devices */
	/* HAL_ADCEx_Calibration_Start */

	(void)HAL_ADC_Start_DMA(&hadc1, (uint32_t*)ADC1Measures, NO_OF_ADC1_MEASURES);
	(void)HAL_ADC_Start_DMA(&hadc3, (uint32_t*)ADC3Measures, NO_OF_ADC3_MEASURES);

	if(NO_ERROR == error) {error = (Error_Code)HAL_TIM_PWM_Start(&htim9, TIM_CHANNEL_1);}
	if(NO_ERROR == error) {error = (Error_Code)HAL_TIM_PWM_Start(&htim9, TIM_CHANNEL_2);}

	if (NO_ERROR != error)
	{
		error = TIM__PWM_START_FAIL;
		my_error_handler(error);
	}

	HAL_Delay(300);

	/* * * * * * * * * * * * * * * * * * * * * * * * * * * * * * * * * * * * */
	/** !!!!TURNING THIS ON WILL ERASE WHOLE EEPROMS!!!! **/
#if 0
error = EraseWholeEEPROM(&EEPROM_car);
	if(NO_ERROR != error)
	{
		error = EEPROM__WHOLE_MEMORY_ERASE_FAIL;
		my_error_handler(error);
	}
#endif

#if 0
error = EraseWholeEEPROM(&EEPROM_board);
	if(NO_ERROR != error)
	{
		error = EEPROM__WHOLE_MEMORY_ERASE_FAIL;
		my_error_handler(error);
	}
#endif
	/* * * * * * * * * * * * * * * * * * * * * * * * * * * * * * * * * * * * */

  /* USER CODE END 2 */

  /* Call init function for freertos objects (in freertos.c) */
  MX_FREERTOS_Init();
  /* Start scheduler */
  osKernelStart();

  /* We should never get here as control is now taken by the scheduler */
  /* Infinite loop */
  /* USER CODE BEGIN WHILE */
	while (1)
	{
		error = OS__MAIN_WHILE_LOOP_REACHED;
		my_error_handler(error);
    /* USER CODE END WHILE */

	}
}

void SystemClock_Config(void)
{
  RCC_OscInitTypeDef RCC_OscInitStruct = {0};
  RCC_ClkInitTypeDef RCC_ClkInitStruct = {0};

  /** Configure the main internal regulator output voltage
  */
  __HAL_RCC_PWR_CLK_ENABLE();
  __HAL_PWR_VOLTAGESCALING_CONFIG(PWR_REGULATOR_VOLTAGE_SCALE1);
  /** Initializes the RCC Oscillators according to the specified parameters
  * in the RCC_OscInitTypeDef structure.
  */
  RCC_OscInitStruct.OscillatorType = RCC_OSCILLATORTYPE_LSI|RCC_OSCILLATORTYPE_HSE;
  RCC_OscInitStruct.HSEState = RCC_HSE_ON;
  RCC_OscInitStruct.LSIState = RCC_LSI_ON;
  RCC_OscInitStruct.PLL.PLLState = RCC_PLL_ON;
  RCC_OscInitStruct.PLL.PLLSource = RCC_PLLSOURCE_HSE;
  RCC_OscInitStruct.PLL.PLLM = 8;
  RCC_OscInitStruct.PLL.PLLN = 168;
  RCC_OscInitStruct.PLL.PLLP = RCC_PLLP_DIV2;
  RCC_OscInitStruct.PLL.PLLQ = 7;
  if (HAL_RCC_OscConfig(&RCC_OscInitStruct) != HAL_OK)
  {
    Error_Handler();
  }
  /** Initializes the CPU, AHB and APB buses clocks
  */
  RCC_ClkInitStruct.ClockType = RCC_CLOCKTYPE_HCLK|RCC_CLOCKTYPE_SYSCLK
                              |RCC_CLOCKTYPE_PCLK1|RCC_CLOCKTYPE_PCLK2;
  RCC_ClkInitStruct.SYSCLKSource = RCC_SYSCLKSOURCE_PLLCLK;
  RCC_ClkInitStruct.AHBCLKDivider = RCC_SYSCLK_DIV1;
  RCC_ClkInitStruct.APB1CLKDivider = RCC_HCLK_DIV4;
  RCC_ClkInitStruct.APB2CLKDivider = RCC_HCLK_DIV2;

  if (HAL_RCC_ClockConfig(&RCC_ClkInitStruct, FLASH_LATENCY_5) != HAL_OK)
  {
    Error_Handler();
  }
}

/* USER CODE BEGIN 4 */

/* UART communication via Interrupts handling */
void HAL_UART_RxCpltCallback(UART_HandleTypeDef *huart)
{
	static uint8_t counter = 0;
	static uint8_t nCounter = 0;
	static uint8_t rCounter = 0;
	static uint8_t dataStarted = 0; /* Set when "$" (so the first sign in the string) is found and Reset when string ends (after second \n\r */

#ifdef GPS_RECEIVING
	/* Checking if interrupt is from UART1 (GPS) */
	if (&huart1 == huart)
	{
		if (FALSE == GPS.DataReady)
		{
			if ('$' == GPS.receivedByte)
				dataStarted = TRUE;

			if (TRUE == dataStarted)
			{
				if ('\r' == GPS.receivedByte)
				{
					++rCounter;
					GPS.GPS_buffer[counter] = GPS.receivedByte;
					++counter;
				}
				else
				{
					if ('\n' == GPS.receivedByte)
					{
						++nCounter;
						GPS.GPS_buffer[counter] = GPS.receivedByte;
						++counter;
					}
					else
					{
						if (((NUMBER_OF_R_AND_N_SIGNS > rCounter) || (NUMBER_OF_R_AND_N_SIGNS > nCounter)) && (GPS_BUFFER_SIZE > counter))
						{
							GPS.GPS_buffer[counter] = GPS.receivedByte;
							++counter;
						}
						else
						{
							GPS.DataReady = TRUE;
							counter = 0;
							rCounter = 0;
							nCounter = 0;
							dataStarted = FALSE;
						}    //if((2 > rCounter) || (2 > nCounter))
					}    //if('\n' == GPS.receivedByte)
				}    //if('\r' == GPS.receivedByte)
			}    //if(TRUE == dataStarted)
		}    //if(FALSE == GPS.DataReady)

		HAL_UART_Receive_IT(&huart1, (uint8_t*)(&GPS.receivedByte), 1u);
	}    //if(&huart1 == *huart)
#endif
}

void HAL_GPIO_EXTI_Callback(uint16_t GPIO_Pin)
{
	static uint32_t lastTimerCounter_ENC_MENU = 0;
	static uint32_t lastTimerCounter_ENC_CRUISE = 0;
	Error_Code error = NO_ERROR;

	/* Checking if brake or clutch pedals were pushed in - turning off the cruise control */
	if((BRAKE_PEDAL_Pin == GPIO_Pin) || (CLUTCH_PEDAL_Pin == GPIO_Pin))
	{
		Complete_Shutdown();
	}

	/* Checking if interrupt is from ENC_BUTTON pin for menu*/
	if (ENC_BUTTON_MENU_Pin == GPIO_Pin)
	{
		if ((Tim7_Counter_100us - lastTimerCounter_ENC_MENU) > (DEBOUNCING_TIME_FOR_ENCODER_BUTTON * 10U) /*ms*/)
		{
			if (GPIO_PIN_RESET == HAL_GPIO_ReadPin(ENC_BUTTON_MENU_GPIO_Port, ENC_BUTTON_MENU_Pin)) /*Button Pushed In*/
			{
				error = (Error_Code)osTimerStart(My_Timer_ENC_Menu_ButtonHandle, ENC_BUTTON_LONG_PRESS_TIME);
				if (NO_ERROR != error)
				{
					error = OS__STARTING_TIMER_FAILED;
					my_error_handler(error);
				}
			}
			else /*Button Released*/
			{
				if (FALSE == ENC_button_menu.longPressInfoForISR) /* If long press was NOT detected then it is a short press */
				{
					error = (Error_Code)osTimerStop(My_Timer_ENC_Menu_ButtonHandle); /* Stop the timer */
					if (NO_ERROR != error)
					{
						error = OS__STOPPING_TIMER_FAILED;
						my_error_handler(error);
					}
					ENC_button_menu.allFlags = 0b00001001; /* shortPressDetected and shortPressDetectedBuzzer set to 1 */
					backlightOnRequest = TRUE;	/* Turn back-light on due to an action */
				}
				else /* Long press was detected so do not set short press and reset the flag for ISR for the next time */
				{
					ENC_button_menu.longPressInfoForISR = FALSE;
				}

			}
			lastTimerCounter_ENC_MENU = Tim7_Counter_100us;
		}
	}

	/* Checking if interrupt is from ENC_BUTTON pin for cruise control*/
	if (ENC_BUTTON_CRUISE_Pin == GPIO_Pin)
	{
		if ((Tim7_Counter_100us - lastTimerCounter_ENC_CRUISE) > (DEBOUNCING_TIME_FOR_ENCODER_BUTTON * 10U) /*ms*/)
		{
			if (GPIO_PIN_RESET == HAL_GPIO_ReadPin(ENC_BUTTON_CRUISE_GPIO_Port, ENC_BUTTON_CRUISE_Pin)) /*Button Pushed In*/
			{
				error = (Error_Code)osTimerStart(My_Timer_ENC_Cruise_ButtonHandle, ENC_BUTTON_LONG_PRESS_TIME);
				if (NO_ERROR != error)
				{
					error = OS__STARTING_TIMER_FAILED;
					my_error_handler(error);
				}
			}
			else /*Button Released*/
			{
				if (FALSE == ENC_button_cruise.longPressInfoForISR) /* If long press was NOT detected then it is a short press */
				{
					error = (Error_Code)osTimerStop(My_Timer_ENC_Cruise_ButtonHandle); /* Stop the timer */
					if (NO_ERROR != error)
					{
						error = OS__STOPPING_TIMER_FAILED;
						my_error_handler(error);
					}
					ENC_button_cruise.allFlags = 0b00001001; /* shortPressDetected and shortPressDetectedBuzzer set to 1 */
					backlightOnRequest = TRUE;	/* Turn back-light on due to an action */
				}
				else /* Long press was detected so do not set short press and reset the flag for ISR for the next time */
				{
					ENC_button_cruise.longPressInfoForISR = FALSE;
				}

			}
			lastTimerCounter_ENC_CRUISE = Tim7_Counter_100us;
		}
	}

	/* Count RPM signals */
	if(RPM_SIGNAL_Pin == GPIO_Pin)
	{
		++RPM_counter;
	}

	/* Count Speed signals */
	if(SPEED_SIGNAL_Pin == GPIO_Pin)
	{
		++SPEED_counter;
	}
}

/* USER CODE END 4 */

 /**
  * @brief  Period elapsed callback in non blocking mode
  * @note   This function is called  when TIM6 interrupt took place, inside
  * HAL_TIM_IRQHandler(). It makes a direct call to HAL_IncTick() to increment
  * a global variable "uwTick" used as application time base.
  * @param  htim : TIM handle
  * @retval None
  */
void HAL_TIM_PeriodElapsedCallback(TIM_HandleTypeDef *htim)
{
  if (htim->Instance == TIM6) {
    HAL_IncTick();
  }
  /* USER CODE BEGIN Callback 1 */

	/* Timer 7 is used for stats and for time counting (resolution is 100us) */
	if (&htim7 == htim)
	{
		++Tim7_Counter_100us;
	}

  /* USER CODE END Callback 1 */
}

void Error_Handler(void)
{
  /* USER CODE BEGIN Error_Handler_Debug */
	/* User can add his own implementation to report the HAL error return state */

	my_error_handler(UNKNOWN_ERROR);

  /* USER CODE END Error_Handler_Debug */
}

/************************ (C) COPYRIGHT STMicroelectronics *****END OF FILE****/

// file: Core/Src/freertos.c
/* USER CODE BEGIN Header */
/**
  ******************************************************************************
  * File Name          : freertos.c
  * Description        : Code for freertos applications
  ******************************************************************************
  * @attention
  *
  * <h2><center>&copy; Copyright (c) 2021 STMicroelectronics.
  * All rights reserved.</center></h2>
  *
  * This software component is licensed by ST under Ultimate Liberty license
  * SLA0044, the "License"; You may not use this file except in compliance with
  * the License. You may obtain a copy of the License at:
  *                             www.st.com/SLA0044
  *
  ******************************************************************************
  */
/* USER CODE END Header */

#include "FreeRTOS.h"
#include "task.h"
#include "main.h"
#include "cmsis_os.h"

/* USER CODE BEGIN Includes */

#include "../VariousFunctions/Functions.h"
#include "../GPS/GPS_Parsing.h"
#include "../EEPROM/EEPROM.h"
#include "Init_Functions.h"

#include "fatfs.h"
#include "sdio.h"

/* USER CODE END Includes */

/* USER CODE BEGIN Variables */

/* * * * * * * * * * * * * * * * * * * * * * * * * * * * * * * * * * * * */
extern I2C_HandleTypeDef hi2c1;
extern I2C_HandleTypeDef hi2c3;
extern TIM_HandleTypeDef htim8;
extern SD_HandleTypeDef hsd;
extern IWDG_HandleTypeDef hiwdg;

extern boolean backlightOnRequest;

#ifdef RUNTIME_STATS_TIMER_CONFIG
extern TIM_HandleTypeDef htim7;
#endif
/* * * * * * * * * * * * * * * * * * * * * * * * * * * * * * * * * * * * */

/* * * * * * * * * * * * * * * * * * * * * * * * * * * * * * * * * * * * */
/* To indicate that the system is fully initialized */
boolean SYSTEM_IS_UP_FLAG = FALSE;

/* For debugging - task time etc. */
volatile uint32_t Tim7_Counter_100us = 0u;

/* Engine and Car Parameters */
volatile uint32_t RPM_counter = 0u;
volatile uint32_t SPEED_counter = 0u;

/* For Signaling ENC button and scroll for the menu */
volatile ENCButton_struct ENC_button_menu =
	{ 0 };
volatile int8_t EncoderCounterMenuDiff = 0;

/* For Signaling ENC button and scroll for the cruise control */
volatile ENCButton_struct ENC_button_cruise =
	{ 0 };
volatile int8_t EncoderCounterCruiseDiff = 0;

/* For measurements from ADC1 and ADC3 */
volatile uint16_t ADC1Measures[NO_OF_ADC1_MEASURES] =
	{ 0u };
volatile uint16_t ADC3Measures[NO_OF_ADC3_MEASURES] =
	{ 0u };

/* For GPS data, buffering, messages for LCD */
GPS_data_struct GPS =
	{    //.TimeZoneAdjPoland = 2,/* .homeLatitude = 52.093731, .homeLongitude = 20.661411,*/
		.forLCD.hours.messageReadyFLAG = FALSE,
		.forLCD.minutes.messageReadyFLAG = FALSE,
		.forLCD.seconds.messageReadyFLAG = FALSE,
		.forLCD.clock.messageReadyFLAG = FALSE,
		.forLCD.latitude.messageReadyFLAG = FALSE,
		.forLCD.latitudeIndicator.messageReadyFLAG = FALSE,
		.forLCD.longitude.messageReadyFLAG = FALSE,
		.forLCD.longitudeIndicator.messageReadyFLAG = FALSE,
		.forLCD.status.messageReadyFLAG = FALSE,
		.forLCD.satellitesUsed.messageReadyFLAG =
		FALSE,
		.forLCD.altitude.messageReadyFLAG = FALSE,
		.forLCD.speed.messageReadyFLAG = FALSE };

/* * * * * * * * * * * * * * * * * * * * * * * * * * * * * * * * * * * * */
/* For SDCard parameters, settings, information */
SDCard_info_struct SDCard_info =
	{ 0 };

/* * * * * * * * * * * * * * * * * * * * * * * * * * * * * * * * * * * * */
/* For LCD parameters and settings */
LCD_parameters_struct LCD =
	{ 	.addressLCD = LCD_I2C_ADDRESS,
		.noOfRowsLCD = NO_OF_ROWS_IN_LCD,
		.noOfColumnsLCD = NO_OF_COLUMNS_IN_LCD };

/* * * * * * * * * * * * * * * * * * * * * * * * * * * * * * * * * * * * */
/* For measuring Board temperatures with usage of NTC parameters */
NTC_parameters_struct NTC =
	{ 	.Beta = 4250.0,
		.R25 = 100000.0,
		.Rgnd = 10000.0,
		.T25 = 298.0,
		.beta_x_T25 = 1266500.0 };

/* * * * * * * * * * * * * * * * * * * * * * * * * * * * * * * * * * * * */
/* Counter for CAR EEPROM */
CAR_EEPROM_counters_struct CAR_EEPROM_counters =
	{ 0 };

/* For CAR EEPROM usage, its addressing and blocking */
EEPROM_parameters_struct EEPROM_car =
	{ 	.EEPROM_hi2c = &hi2c3,
		.address = EEPROM_CAR_ADDRESS,
		.pin = EEPROM_CAR_BLOCK_PIN,
		.port = EEPROM_CAR_BLOCK_PORT };

/* CAR SETTINGS and VALUES*/
waterTempSettings_struct CAR_waterTemp =
	{ 0 };
carTemperature_type waterTemperatureValue = 0.0;
LCD_message waterTemperatureValueForLCD =
	{ 	.messageHandler = NULL,
		.size = 0,
		.messageReadyFLAG = 0 };

oilTempSettings_struct CAR_oilTemp =
	{ 0 };
carTemperature_type oilTemperatureValue = 0.0;
LCD_message oilTemperatureValueForLCD =
	{ 	.messageHandler = NULL,
		.size = 0,
		.messageReadyFLAG = 0 };

oilPressureSettings_struct CAR_oilPressure =
	{ 0 };
#ifdef OIL_PRESSURE_ANALOG_SENSOR
carOilAnalogPressure_type oilPressureValue = 0.0;
LCD_message oilPressureValueForLCD =
	{ 	.messageHandler = NULL,
		.size = 0,
		.messageReadyFLAG = 0 };
#endif
#ifdef OIL_PRESSURE_BINARY_SENSOR
carOilBinaryPressure_type oilPressureValueBinary = NOK;
LCD_message oilPressureValueBinaryForLCD =
	{ 	.messageHandler = NULL,
		.size = 0,
		.messageReadyFLAG = 0 };
#endif

batterySettings_struct CAR_mainBattery =
	{ 0 };
carVoltage_type mainBatteryVoltageValue = 0.0;
LCD_message mainBatteryVoltageValueForLCD =
	{ 	.messageHandler = NULL,
		.size = 0,
		.messageReadyFLAG = 0 };

batterySettings_struct CAR_auxiliaryBattery =
	{ 0 };
carVoltage_type auxiliaryBatteryVoltageValue = 0.0;
LCD_message auxiliaryBatteryVoltageValueForLCD =
	{ 	.messageHandler = NULL,
		.size = 0,
		.messageReadyFLAG = 0 };

fuelSettings_struct CAR_fuel =
	{ 0 };
cafFuelLevel_type fuelLevelValue = 0.0;
LCD_message fuelLevelValueForLCD =
	{ 	.messageHandler = NULL,
		.size = 0,
		.messageReadyFLAG = 0 };
/* * * * * * * * * * * * * * * * * * * * * * * * * * * * * * * * * * * * */

/* * * * * * * * * * * * * * * * * * * * * * * * * * * * * * * * * * * * */
/* Counters for BOARD EEPROM */
BOARD_EEPROM_counters_struct BOARD_EEPROM_counters =
	{ 0 };

/* For BOARD EEPROM usage, its addressing and blocking */
EEPROM_parameters_struct EEPROM_board =
	{ 	.EEPROM_hi2c = &hi2c3,
		.address = EEPROM_BOARD_ADDRESS,
		.pin = EEPROM_BOARD_BLOCK_PIN,
		.port = EEPROM_BOARD_BLOCK_PORT };

/* CAR SETTINGS and VALUES*/
boardVoltagesSettings_struct BOARD_voltage =
	{ 0 };
boardVoltage_type voltage3V3 = 0.0;
boardVoltage_type voltage5V = 0.0;
boardVoltage_type voltageIn = 0.0;

LCD_message voltage3V3ForLCD =
	{ 	.messageHandler = NULL,
		.size = 0,
		.messageReadyFLAG = 0 };
LCD_message voltage5VForLCD =
	{ 	.messageHandler = NULL,
		.size = 0,
		.messageReadyFLAG = 0 };
LCD_message voltageInForLCD =
	{ 	.messageHandler = NULL,
		.size = 0,
		.messageReadyFLAG = 0 };

boardTemperaturesSettings_struct BOARD_temperature =
	{ 0 };
boardTemperature_type temperature3V3DCDC = 0.0;
boardTemperature_type temperature5VDCDC = 0.0;
boardTemperature_type temperatureHBridge = 0.0;

LCD_message temperature3V3DCDCForLCD =
	{ 	.messageHandler = NULL,
		.size = 0,
		.messageReadyFLAG = 0 };
LCD_message temperature5VDCDCForLCD =
	{ 	.messageHandler = NULL,
		.size = 0,
		.messageReadyFLAG = 0 };
LCD_message temperatureHBridgeForLCD =
	{ 	.messageHandler = NULL,
		.size = 0,
		.messageReadyFLAG = 0 };

buzzerMainSettings_struct BUZZER_settings =
	{ 0 };
LCDMainSettings_struct LCD_MainSettings =
	{ 0 };
/* * * * * * * * * * * * * * * * * * * * * * * * * * * * * * * * * * * * */

/* * * * * * * * * * * * * * * * * * * * * * * * * * * * * * * * * * * * */
/* Counters for FRAM */

/* For FRAMM usage, its addressing and blocking */
EEPROM_parameters_struct FRAM_parameters =
	{ 	.EEPROM_hi2c = &hi2c1,
		.address = FRAM_ADDRESS,
		.pin = FRAM_BLOCK_PIN,
		.port = FRAM_BLOCK_PORT };

CAR_mileage_struct CAR_mileage =
	{ 0 };
LCD_message totalMileageForLCD =
	{ 	.messageHandler = NULL,
		.size = 0,
		.messageReadyFLAG = 0 };
LCD_message tripMileageForLCD =
	{ 	.messageHandler = NULL,
		.size = 0,
		.messageReadyFLAG = 0 };
/* * * * * * * * * * * * * * * * * * * * * * * * * * * * * * * * * * * * */

/* Car information (Key, Engine status etc.) */
CarStateinfo_type CarStateInfo =
	{ 0 };
LCD_message RPMForLCD =
	{ 	.messageHandler = NULL,
		.size = 0,
		.messageReadyFLAG = 0 };
LCD_message SPEEDForLCD =
	{ 	.messageHandler = NULL,
		.size = 0,
		.messageReadyFLAG = 0 };

/* * * * * * * * * * * * * * * * * * * * * * * * * * * * * * * * * * * * */
/* Constant value limits and check - hard-coded, to be changed only by recompilation */
GlobalValuesLimits_struct GlobalValuesLimits =
	{ 	.polishTimeAdj_min = 0,
		.polishTimeAdj_max = 1,
		.timeZoneAdj_min = -12,
		.timeZoneAdj_max = 12,

		.waterHighTempWarningThreshold_min = 50,
		.waterHighTempWarningThreshold_max = 150,
		.waterHighTempAlarmThreshold_min = 50,
		.waterHighTempAlarmThreshold_max = 150,
		.waterHighTempFanOnThreshold_min = 50,
		.waterHighTempFanOnThreshold_max = 150,
		.waterHighTempFanOffThreshold_min = 50,
		.waterHighTempFanOffThreshold_max = 150,

		.oilHighTempWarningThreshold_min = 50,
		.oilHighTempWarningThreshold_max = 150,
		.oilHighTempAlarmThreshold_min = 50,
		.oilHighTempAlarmThreshold_max = 150,

		.oilHighPressureAlarmThreshold_min = 0.1,
		.oilHighPressureAlarmThreshold_max = 7.5,
		.oilLowPressureAlarmThreshold_min = 0.1,
		.oilLowPressureAlarmThreshold_max = 7.5,

		.batteryLowVoltageAlarmThreshold_min = 8.00,
		.batteryLowVoltageAlarmThreshold_max = 18.00,
		.batteryHighVoltageAlarmThreshold_min = 8.00,
		.batteryHighVoltageAlarmThreshold_max = 18.00,

		.fuelLowLevelWarningThreshold_min = 5,
		.fuelLowLevelWarningThreshold_max = 80,

		.board3V3SupplyLowThreshold_min = 1.80,
		.board3V3SupplyLowThreshold_max = 4.00,
		.board3V3SupplyHighThreshold_min = 1.80,
		.board3V3SupplyHighThreshold_max = 4.00,
		.board5VSupplyLowThreshold_min = 4.00,
		.board5VSupplyLowThreshold_max = 6.00,
		.board5VSupplyHighThreshold_min = 4.00,
		.board5VSupplyHighThreshold_max = 6.00,
		.boardVinSupplyLowThreshold_min = 6.00,
		.boardVinSupplyLowThreshold_max = 17.00,

		.board5VDCDCTemperatureHighThreshold_min = 20,
		.board5VDCDCTemperatureHighThreshold_max = 150,
		.board3V3DCDCTemperatureHighThreshold_min = 20,
		.board3V3DCDCTemperatureHighThreshold_max = 150,
		.boardHBridgeTemperatureHighThreshold_min = 20,
		.boardHBridgeTemperatureHighThreshold_max = 150,

		.homeScreen_min = MainMenu_Layer,
		.homeScreen_max = JarvisInfo_Layer,
		.autoHomeReturnTime_min = 0,
		.autoHomeReturnTime_max = 255,
		.backlightLevel_min = 3,
		.backlightLevel_max = 10000,
		.backlightOffLevel_min = 0,
		.backlightOffLevel_max = 1000,
		.secondsToAutoTurnOffBacklight_min = 0,
		.secondsToAutoTurnOffBacklight_max = 255,
		.autoBacklightOffHourStart_min = 0,
		.autoBacklightOffHourStart_max = 24,
		.autoBacklightOffHourEnd_min = 0,
		.autoBacklightOffHourEnd_max = 24 };
/* * * * * * * * * * * * * * * * * * * * * * * * * * * * * * * * * * * * */

/* USER CODE END Variables */
osThreadId My_StartUp_TaskHandle;
osThreadId My_CruiseCntrlHandle;
osThreadId My_500ms_TaskHandle;
osThreadId My_LCD_TaskHandle;
osThreadId My_GPS_TaskHandle;
osThreadId My_EEPROM_TaskHandle;
osThreadId My_DumpToEEPROMHandle;
osThreadId My_DumpToSDCardHandle;
osThreadId My_Measure_TaskHandle;
osThreadId My_50ms_TaskHandle;
osThreadId My_DiagCheck_TaHandle;
osThreadId My_AlarmControlHandle;
osMessageQId Queue_EEPROM_readHandle;
osMessageQId Queue_EEPROM_writeHandle;
osMessageQId Queue_error_snapshot_dumpHandle;
osMessageQId Queue_diagnostic_snapshot_dumpHandle;
osTimerId My_Timer_ENC_Menu_ButtonHandle;
osTimerId My_Timer_ENC_Cruise_ButtonHandle;
osTimerId My_Timer_carWaterTempValueCheckHandle;
osTimerId My_Timer_carOilTempValueCheckHandle;
osTimerId My_Timer_carOilAnalogPressureValueCheckHandle;
osTimerId My_Timer_carMainBattVoltageValueCheckHandle;
osTimerId My_Timer_carFuelLevelValueCheckHandle;
osTimerId My_Timer_board3V3VoltageValueCheckHandle;
osTimerId My_Timer_board5VVoltageValueCheckHandle;
osTimerId My_Timer_boardVinVoltageValueCheckHandle;
osTimerId My_Timer_board3V3TempValueCheckHandle;
osTimerId My_Timer_board5VTempValueCheckHandle;
osTimerId My_Timer_boardHBridgeTempValueCheckHandle;
osTimerId My_Timer_carOilBinaryPressureValueCheckHandle;
osTimerId My_Timer_BuzzerHandle;
osTimerId My_Timer_carAuxBattVoltageValueCheckHandle;
osTimerId My_Timer_LCD_BacklightHandle;
osTimerId My_Timer_WIPERSHandle;

void StartStartUpTask(void const * argument);
extern void StartCruiseCntrlTask(void const * argument);
extern void Start500msTask(void const * argument);
extern void StartLCDTask(void const * argument);
extern void StartGPSTask(void const * argument);
extern void StartEEPROMTask(void const * argument);
extern void StartDumpToEEPROMTask(void const * argument);
extern void StartDumpToSDCardTask(void const * argument);
extern void StartMeasureTask(void const * argument);
extern void Start50msTask(void const * argument);
extern void StartDiagCheckTask(void const * argument);
extern void StartAlarmControlTask(void const * argument);
void ENC_Menu_Button_LongPress_Callback(void const * argument);
void ENC_Cruise_Button_LongPress_Callback(void const * argument);
extern void Timer_carWaterTempValueCheck(void const * argument);
extern void Timer_carOilTempValueCheck(void const * argument);
extern void Timer_carOilAnalogPressureValueCheck(void const * argument);
extern void Timer_carMainBattVoltageValueCheck(void const * argument);
extern void Timer_carFuelLevelValueCheck(void const * argument);
extern void Timer_board3V3VoltageValueCheck(void const * argument);
extern void Timer_board5VVoltageValueCheck(void const * argument);
extern void Timer_boardVinVoltageValueCheck(void const * argument);
extern void Timer_board3V3TempValueCheck(void const * argument);
extern void Timer_board5VTempValueCheck(void const * argument);
extern void Timer_boardHBridgeTempValueCheck(void const * argument);
extern void Timer_carOilBinaryPressureValueCheck(void const * argument);
extern void Timer_Buzzer(void const * argument);
extern void Timer_carAuxBattVoltageValueCheck(void const * argument);
extern void Timer_LCD_Backlight(void const * argument);
extern void Timer_WIPERS(void const * argument);

extern void MX_USB_DEVICE_Init(void);
void MX_FREERTOS_Init(void); /* (MISRA C 2004 rule 8.1) */

/* GetIdleTaskMemory prototype (linked to static allocation support) */
void vApplicationGetIdleTaskMemory( StaticTask_t **ppxIdleTaskTCBBuffer, StackType_t **ppxIdleTaskStackBuffer, uint32_t *pulIdleTaskStackSize );

/* GetTimerTaskMemory prototype (linked to static allocation support) */
void vApplicationGetTimerTaskMemory( StaticTask_t **ppxTimerTaskTCBBuffer, StackType_t **ppxTimerTaskStackBuffer, uint32_t *pulTimerTaskStackSize );

/* Hook prototypes */
void configureTimerForRunTimeStats(void);
unsigned long getRunTimeCounterValue(void);
void vApplicationStackOverflowHook(TaskHandle_t xTask, signed char *pcTaskName);
void vApplicationMallocFailedHook(void);

/* USER CODE BEGIN 1 */
/* Functions needed when configGENERATE_RUN_TIME_STATS is on */
__weak void configureTimerForRunTimeStats(void)
{ /* FOR DEBUGGING */
#ifdef RUNTIME_STATS_TIMER_CONFIG
	HAL_TIM_Base_Start_IT(&htim7);
#endif
}

__weak unsigned long getRunTimeCounterValue(void)
{ /* FOR DEBUGGING */
#ifdef RUNTIME_STATS_TIMER_CONFIG
	return Tim7_Counter_100us;
#endif
}
/* USER CODE END 1 */

/* USER CODE BEGIN 4 */
__weak void vApplicationStackOverflowHook(TaskHandle_t xTask, signed char *pcTaskName)
{
   /* Run time stack overflow checking is performed if
   configCHECK_FOR_STACK_OVERFLOW is defined to 1 or 2. This hook function is
   called if a stack overflow is detected. */
}
/* USER CODE END 4 */

/* USER CODE BEGIN 5 */
__weak void vApplicationMallocFailedHook(void)
{
   /* vApplicationMallocFailedHook() will only be called if
   configUSE_MALLOC_FAILED_HOOK is set to 1 in FreeRTOSConfig.h. It is a hook
   function that will get called if a call to pvPortMalloc() fails.
   pvPortMalloc() is called internally by the kernel whenever a task, queue,
   timer or semaphore is created. It is also called by various parts of the
   demo application. If heap_1.c or heap_2.c are used, then the size of the
   heap available to pvPortMalloc() is defined by configTOTAL_HEAP_SIZE in
   FreeRTOSConfig.h, and the xPortGetFreeHeapSize() API function can be used
   to query the size of free heap space that remains (although it does not
   provide information on how the remaining heap might be fragmented). */
}
/* USER CODE END 5 */

/* USER CODE BEGIN GET_IDLE_TASK_MEMORY */
static StaticTask_t xIdleTaskTCBBuffer;
static StackType_t xIdleStack[configMINIMAL_STACK_SIZE];

void vApplicationGetIdleTaskMemory( StaticTask_t **ppxIdleTaskTCBBuffer, StackType_t **ppxIdleTaskStackBuffer, uint32_t *pulIdleTaskStackSize )
{
  *ppxIdleTaskTCBBuffer = &xIdleTaskTCBBuffer;
  *ppxIdleTaskStackBuffer = &xIdleStack[0];
  *pulIdleTaskStackSize = configMINIMAL_STACK_SIZE;
  /* place for user code */
}
/* USER CODE END GET_IDLE_TASK_MEMORY */

/* USER CODE BEGIN GET_TIMER_TASK_MEMORY */
static StaticTask_t xTimerTaskTCBBuffer;
static StackType_t xTimerStack[configTIMER_TASK_STACK_DEPTH];

void vApplicationGetTimerTaskMemory( StaticTask_t **ppxTimerTaskTCBBuffer, StackType_t **ppxTimerTaskStackBuffer, uint32_t *pulTimerTaskStackSize )
{
  *ppxTimerTaskTCBBuffer = &xTimerTaskTCBBuffer;
  *ppxTimerTaskStackBuffer = &xTimerStack[0];
  *pulTimerTaskStackSize = configTIMER_TASK_STACK_DEPTH;
  /* place for user code */
}
/* USER CODE END GET_TIMER_TASK_MEMORY */

void MX_FREERTOS_Init(void) {

  /* Create the timer(s) */
  /* definition and creation of My_Timer_ENC_Menu_Button */
  osTimerDef(My_Timer_ENC_Menu_Button, ENC_Menu_Button_LongPress_Callback);
  My_Timer_ENC_Menu_ButtonHandle = osTimerCreate(osTimer(My_Timer_ENC_Menu_Button), osTimerOnce, NULL);

  /* definition and creation of My_Timer_ENC_Cruise_Button */
  osTimerDef(My_Timer_ENC_Cruise_Button, ENC_Cruise_Button_LongPress_Callback);
  My_Timer_ENC_Cruise_ButtonHandle = osTimerCreate(osTimer(My_Timer_ENC_Cruise_Button), osTimerOnce, NULL);

  /* definition and creation of My_Timer_carWaterTempValueCheck */
  osTimerDef(My_Timer_carWaterTempValueCheck, Timer_carWaterTempValueCheck);
  My_Timer_carWaterTempValueCheckHandle = osTimerCreate(osTimer(My_Timer_carWaterTempValueCheck), osTimerOnce, NULL);

  /* definition and creation of My_Timer_carOilTempValueCheck */
  osTimerDef(My_Timer_carOilTempValueCheck, Timer_carOilTempValueCheck);
  My_Timer_carOilTempValueCheckHandle = osTimerCreate(osTimer(My_Timer_carOilTempValueCheck), osTimerOnce, NULL);

  /* definition and creation of My_Timer_carOilAnalogPressureValueCheck */
  osTimerDef(My_Timer_carOilAnalogPressureValueCheck, Timer_carOilAnalogPressureValueCheck);
  My_Timer_carOilAnalogPressureValueCheckHandle = osTimerCreate(osTimer(My_Timer_carOilAnalogPressureValueCheck), osTimerOnce, NULL);

  /* definition and creation of My_Timer_carMainBattVoltageValueCheck */
  osTimerDef(My_Timer_carMainBattVoltageValueCheck, Timer_carMainBattVoltageValueCheck);
  My_Timer_carMainBattVoltageValueCheckHandle = osTimerCreate(osTimer(My_Timer_carMainBattVoltageValueCheck), osTimerOnce, NULL);

  /* definition and creation of My_Timer_carFuelLevelValueCheck */
  osTimerDef(My_Timer_carFuelLevelValueCheck, Timer_carFuelLevelValueCheck);
  My_Timer_carFuelLevelValueCheckHandle = osTimerCreate(osTimer(My_Timer_carFuelLevelValueCheck), osTimerOnce, NULL);

  /* definition and creation of My_Timer_board3V3VoltageValueCheck */
  osTimerDef(My_Timer_board3V3VoltageValueCheck, Timer_board3V3VoltageValueCheck);
  My_Timer_board3V3VoltageValueCheckHandle = osTimerCreate(osTimer(My_Timer_board3V3VoltageValueCheck), osTimerOnce, NULL);

  /* definition and creation of My_Timer_board5VVoltageValueCheck */
  osTimerDef(My_Timer_board5VVoltageValueCheck, Timer_board5VVoltageValueCheck);
  My_Timer_board5VVoltageValueCheckHandle = osTimerCreate(osTimer(My_Timer_board5VVoltageValueCheck), osTimerOnce, NULL);

  /* definition and creation of My_Timer_boardVinVoltageValueCheck */
  osTimerDef(My_Timer_boardVinVoltageValueCheck, Timer_boardVinVoltageValueCheck);
  My_Timer_boardVinVoltageValueCheckHandle = osTimerCreate(osTimer(My_Timer_boardVinVoltageValueCheck), osTimerOnce, NULL);

  /* definition and creation of My_Timer_board3V3TempValueCheck */
  osTimerDef(My_Timer_board3V3TempValueCheck, Timer_board3V3TempValueCheck);
  My_Timer_board3V3TempValueCheckHandle = osTimerCreate(osTimer(My_Timer_board3V3TempValueCheck), osTimerOnce, NULL);

  /* definition and creation of My_Timer_board5VTempValueCheck */
  osTimerDef(My_Timer_board5VTempValueCheck, Timer_board5VTempValueCheck);
  My_Timer_board5VTempValueCheckHandle = osTimerCreate(osTimer(My_Timer_board5VTempValueCheck), osTimerOnce, NULL);

  /* definition and creation of My_Timer_boardHBridgeTempValueCheck */
  osTimerDef(My_Timer_boardHBridgeTempValueCheck, Timer_boardHBridgeTempValueCheck);
  My_Timer_boardHBridgeTempValueCheckHandle = osTimerCreate(osTimer(My_Timer_boardHBridgeTempValueCheck), osTimerOnce, NULL);

  /* definition and creation of My_Timer_carOilBinaryPressureValueCheck */
  osTimerDef(My_Timer_carOilBinaryPressureValueCheck, Timer_carOilBinaryPressureValueCheck);
  My_Timer_carOilBinaryPressureValueCheckHandle = osTimerCreate(osTimer(My_Timer_carOilBinaryPressureValueCheck), osTimerOnce, NULL);

  /* definition and creation of My_Timer_Buzzer */
  osTimerDef(My_Timer_Buzzer, Timer_Buzzer);
  My_Timer_BuzzerHandle = osTimerCreate(osTimer(My_Timer_Buzzer), osTimerOnce, NULL);

  /* definition and creation of My_Timer_carAuxBattVoltageValueCheck */
  osTimerDef(My_Timer_carAuxBattVoltageValueCheck, Timer_carAuxBattVoltageValueCheck);
  My_Timer_carAuxBattVoltageValueCheckHandle = osTimerCreate(osTimer(My_Timer_carAuxBattVoltageValueCheck), osTimerOnce, NULL);

  /* definition and creation of My_Timer_LCD_Backlight */
  osTimerDef(My_Timer_LCD_Backlight, Timer_LCD_Backlight);
  My_Timer_LCD_BacklightHandle = osTimerCreate(osTimer(My_Timer_LCD_Backlight), osTimerOnce, NULL);

  /* definition and creation of My_Timer_WIPERS */
  osTimerDef(My_Timer_WIPERS, Timer_WIPERS);
  My_Timer_WIPERSHandle = osTimerCreate(osTimer(My_Timer_WIPERS), osTimerOnce, NULL);

  /* Create the queue(s) */
  /* definition and creation of Queue_EEPROM_read */
  osMessageQDef(Queue_EEPROM_read, 5, EEPROM_data_struct);
  Queue_EEPROM_readHandle = osMessageCreate(osMessageQ(Queue_EEPROM_read), NULL);

  /* definition and creation of Queue_EEPROM_write */
  osMessageQDef(Queue_EEPROM_write, 5, EEPROM_data_struct);
  Queue_EEPROM_writeHandle = osMessageCreate(osMessageQ(Queue_EEPROM_write), NULL);

  /* definition and creation of Queue_error_snapshot_dump */
  osMessageQDef(Queue_error_snapshot_dump, 5, Error_Code);
  Queue_error_snapshot_dumpHandle = osMessageCreate(osMessageQ(Queue_error_snapshot_dump), NULL);

  /* definition and creation of Queue_diagnostic_snapshot_dump */
  osMessageQDef(Queue_diagnostic_snapshot_dump, 5, Diagnostic_Snapshot_struct);
  Queue_diagnostic_snapshot_dumpHandle = osMessageCreate(osMessageQ(Queue_diagnostic_snapshot_dump), NULL);

  /* Create the thread(s) */
  /* definition and creation of My_StartUp_Task */
  osThreadDef(My_StartUp_Task, StartStartUpTask, osPriorityHigh, 0, 128);
  My_StartUp_TaskHandle = osThreadCreate(osThread(My_StartUp_Task), NULL);

  /* definition and creation of My_CruiseCntrl */
  osThreadDef(My_CruiseCntrl, StartCruiseCntrlTask, osPriorityAboveNormal, 0, 256);
  My_CruiseCntrlHandle = osThreadCreate(osThread(My_CruiseCntrl), NULL);

  /* definition and creation of My_500ms_Task */
  osThreadDef(My_500ms_Task, Start500msTask, osPriorityNormal, 0, 128);
  My_500ms_TaskHandle = osThreadCreate(osThread(My_500ms_Task), NULL);

  /* definition and creation of My_LCD_Task */
  osThreadDef(My_LCD_Task, StartLCDTask, osPriorityNormal, 0, 512);
  My_LCD_TaskHandle = osThreadCreate(osThread(My_LCD_Task), NULL);

  /* definition and creation of My_GPS_Task */
  osThreadDef(My_GPS_Task, StartGPSTask, osPriorityNormal, 0, 448);
  My_GPS_TaskHandle = osThreadCreate(osThread(My_GPS_Task), NULL);

  /* definition and creation of My_EEPROM_Task */
  osThreadDef(My_EEPROM_Task, StartEEPROMTask, osPriorityAboveNormal, 0, 128);
  My_EEPROM_TaskHandle = osThreadCreate(osThread(My_EEPROM_Task), NULL);

  /* definition and creation of My_DumpToEEPROM */
  osThreadDef(My_DumpToEEPROM, StartDumpToEEPROMTask, osPriorityBelowNormal, 0, 128);
  My_DumpToEEPROMHandle = osThreadCreate(osThread(My_DumpToEEPROM), NULL);

  /* definition and creation of My_DumpToSDCard */
  osThreadDef(My_DumpToSDCard, StartDumpToSDCardTask, osPriorityBelowNormal, 0, 1536);
  My_DumpToSDCardHandle = osThreadCreate(osThread(My_DumpToSDCard), NULL);

  /* definition and creation of My_Measure_Task */
  osThreadDef(My_Measure_Task, StartMeasureTask, osPriorityNormal, 0, 384);
  My_Measure_TaskHandle = osThreadCreate(osThread(My_Measure_Task), NULL);

  /* definition and creation of My_50ms_Task */
  osThreadDef(My_50ms_Task, Start50msTask, osPriorityNormal, 0, 128);
  My_50ms_TaskHandle = osThreadCreate(osThread(My_50ms_Task), NULL);

  /* definition and creation of My_DiagCheck_Ta */
  osThreadDef(My_DiagCheck_Ta, StartDiagCheckTask, osPriorityAboveNormal, 0, 256);
  My_DiagCheck_TaHandle = osThreadCreate(osThread(My_DiagCheck_Ta), NULL);

  /* definition and creation of My_AlarmControl */
  osThreadDef(My_AlarmControl, StartAlarmControlTask, osPriorityNormal, 0, 256);
  My_AlarmControlHandle = osThreadCreate(osThread(My_AlarmControl), NULL);

  /* USER CODE BEGIN RTOS_THREADS */
  /* add threads, ... */

  /* Turning off all threads except the default one - there the initialization will take place */
  vTaskSuspend(My_CruiseCntrlHandle);
  vTaskSuspend(My_500ms_TaskHandle);
  vTaskSuspend(My_Measure_TaskHandle);
  vTaskSuspend(My_50ms_TaskHandle);
  vTaskSuspend(My_AlarmControlHandle);
  vTaskSuspend(My_DiagCheck_TaHandle);
  vTaskSuspend(My_DumpToEEPROMHandle);
  vTaskSuspend(My_DumpToSDCardHandle);
  vTaskSuspend(My_EEPROM_TaskHandle);
  vTaskSuspend(My_GPS_TaskHandle);
  vTaskSuspend(My_LCD_TaskHandle);

  /* USER CODE END RTOS_THREADS */

}

void StartStartUpTask(void const * argument)
{
  /* init code for USB_DEVICE */
  MX_USB_DEVICE_Init();
  /* USER CODE BEGIN StartStartUpTask */

	/* It is unfortunate that USB is the first thing to initialize
	 * however, this is how the CubeMX does it - no control over
	 * that I guess.
	 */

	/***** The following initialization steps are taken: *****\
	 *
	 * Step 0: USB initialization - automatically generated
	 * Step 1: Enable 5V DCDC converter
	 * Step 2: Start sensors and parameters measurements task
	 * Step 3: Start handling of EEPROM requests task
	 * Step 4: Start handling of EEPROM dumps task
	 * Step 5: Start handling of SDCard dumps (with SD initialization) task
	 * Step 6: Start the GPS task
	 * Step 7: Start 1000 milliseconds task
	 * Step 8: Start 500 milliseconds task
	 * Step 9: Start 50 milliseconds task
	 * Step 10: Start LCD task
	 * Step 11: Start Alarm Control task
	 *
	 ***** ***** ***** ***** ***** ***** ***** ***** ***** *****/

  	/* Refresh the IWDG in order not to get a reset in initialization process. */
	(void)HAL_IWDG_Refresh(&hiwdg); /* 600ms till WDG reset */

	/*** Step 1 ***/
 	(void)enable_5VDCDC(); /* Enable 5V DCDC converter */
	osDelay(50U); /* Wait 50ms for the voltage to set properly */

	/*** Step 2 ***/
	vTaskResume(My_EEPROM_TaskHandle); /* Start handling of EEPROM requests */
	osDelay(50U); /* Wait 50ms for the task to run a bit */

	/*** Step 3 ***/
	vTaskResume(My_Measure_TaskHandle); /* Start measurements of parameters and sensors */
	osDelay(50U); /* Wait 50ms for the task to run a bit */

	/*** Step 4 ***/
	vTaskResume(My_DumpToEEPROMHandle); /* Start handling EEPROM Dumps */
	osDelay(50U); /* Wait 50ms for the task to run a bit */

	/*** Step 5 ***/
	vTaskResume(My_DumpToSDCardHandle); /* Start handling SDCard Dumps */
	osDelay(50U); /* Wait 50ms for the task to run a bit */

	/*** Step 6 ***/
	(void)turnOnPower_GPS(); /* Turn on the power */
	vTaskResume(My_GPS_TaskHandle); /* Resume a task */
	osDelay(50U); /* Wait 50ms for the task to run a bit */

	/*** Step 7 ***/
	vTaskResume(My_CruiseCntrlHandle); /* Turn on cruise control task */
	osDelay(50U); /* Wait 50ms for the task to run a bit */

	/*** Step 8 ***/
	vTaskResume(My_500ms_TaskHandle); /* Turn on 500 milliseconds task */
	osDelay(50U); /* Wait 50ms for the task to run a bit */

	/*** Step 9 ***/
	vTaskResume(My_50ms_TaskHandle); /* Turn on 50 milliseconds task */
	osDelay(50U); /* Wait 50ms for the task to run a bit */

	/*** Step 10 ***/
	(void)turnOnPower_LCD(); /* Turn on the power */
	vTaskResume(My_LCD_TaskHandle); /* Turn on LCD task */
	osDelay(50U); /* Wait 50ms for the task to run a bit */

	osDelay(2000U); /* This is to wait for measurements to happen */

	/*** Step 11 ***/
	vTaskResume(My_DiagCheck_TaHandle); /* Turn on Diagnostic task */
	osDelay(1000U); /* Wait 1000ms for the task to run a bit */

	/*** Step 12 ***/
	vTaskResume(My_AlarmControlHandle); /* Turn on Alarm Control task */
	osDelay(50U); /* Wait 50ms for the task to run a bit */

	/* Set the SYSTEM_IS_UP_FLAG to SET */
	SYSTEM_IS_UP_FLAG = TRUE;

	/* After successful start up - suspend the task.
	 * The task could be destroyed but it may be useful later.
	 */
	vTaskSuspend(My_StartUp_TaskHandle);
	/* Infinite loop */
	for (;;)
	{
		/* We should never get here, as the task should be suspended
		 * before getting to the for loop. Thus error handler. */
		my_error_handler(OS__FOR_LOOP_REACHED);
		osDelay(1000); /* Dummy delay - should never be needed. */
	}
  /* USER CODE END StartStartUpTask */
}

/* ENC_Menu_Button_LongPress_Callback function */
void ENC_Menu_Button_LongPress_Callback(void const * argument)
{
  /* USER CODE BEGIN ENC_Menu_Button_LongPress_Callback */

	ENC_button_menu.allFlags |= 0b00010110;
	/* Set 1st, 2nd, 3rd bit to 1 to
	 indicate the long press on bits:
	 longPressDetected,
	 longPressDetectedForISR,
	 longPressDetectedBuzzer */

	backlightOnRequest = TRUE;	/* Turn back-light on due to an action */

  /* USER CODE END ENC_Menu_Button_LongPress_Callback */
}

/* ENC_Cruise_Button_LongPress_Callback function */
void ENC_Cruise_Button_LongPress_Callback(void const * argument)
{
  /* USER CODE BEGIN ENC_Cruise_Button_LongPress_Callback */

	ENC_button_cruise.allFlags |= 0b00010110;
	/* Set 1st, 2nd, 3rd bit to 1 to
	 indicate the long press on bits:
	 longPressDetected,
	 longPressDetectedForISR,
	 longPressDetectedBuzzer */

	backlightOnRequest = TRUE;	/* Turn back-light on due to an action */

  /* USER CODE END ENC_Cruise_Button_LongPress_Callback */
}

/************************ (C) COPYRIGHT STMicroelectronics *****END OF FILE****/
